# MIMXRT1042 register map
Vendor: nxp.com; File version: 1.0
CPU: CM7 r0p1, little endian, MPU, FPU, VTOR, 4 interrupt priority bits
Registers are 32-bit, read-write, reset 0x0 unless marked. A register's access mark holds for its fields unless they carry their own. Offsets are from the block's base; [hi:lo] are bit positions; {n}, {i} and the like mark numbered series; 'fields as' and 'values as' point back to an identical list.

## CAN3 — CAN
Base 0x401D8000
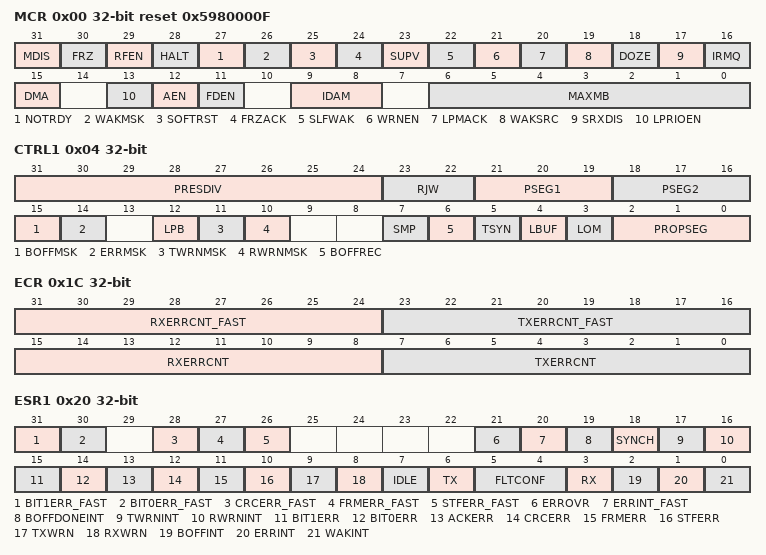
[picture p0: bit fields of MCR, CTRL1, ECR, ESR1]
0x00 MCR reset 0x5980000F — Module Configuration Register
  [31] MDIS — Module Disable
    0=flexcan_enabled (Enable the FlexCAN module.); 1=flexcan_disabled (Disable the FlexCAN module.)
  [30] FRZ — Freeze Enable
    0=freeze_mode_disabled (Not enabled to enter Freeze mode.); 1=freeze_mode_enabled (Enabled to enter Freeze mode.)
  [29] RFEN — Rx FIFO Enable
    0=id2 (Rx FIFO not enabled.); 1=id4 (Rx FIFO enabled.)
  [28] HALT — Halt FlexCAN
    0=HALT_disable (No Freeze mode request.); 1=HALT_enable (Enters Freeze mode if the FRZ bit is asserted.)
  [27] NOTRDY ro — FlexCAN Not Ready
    0=id1 (FlexCAN module is either in Normal mode, Listen-Only mode, or Loop-Back mode.); 1=id2 (FlexCAN module is either in Disable mode, Doze mode, Stop mode, or Freeze mode.)
  [26] WAKMSK — Wake Up Interrupt Mask
    0=wakeup_interrupt_disabled (Wake Up interrupt is disabled.); 1=wakeup_interrupt_enabled (Wake Up interrupt is enabled.)
  [25] SOFTRST — Soft Reset
    0=SOFTRST_no_reset_request (No reset request.); 1=SOFTRST_reset_registers (Resets the registers affected by soft reset.)
  [24] FRZACK ro — Freeze Mode Acknowledge
    0=freeze_mode_no (FlexCAN not in Freeze mode, prescaler running.); 1=freeze_mode_yes (FlexCAN in Freeze mode, prescaler stopped.)
  [23] SUPV — Supervisor Mode
    0=id2 (FlexCAN is in User mode. Affected registers allow both Supervisor and Unrestricted accesses.); 1=id4 (FlexCAN is in Supervisor mode. Affected registers allow only Supervisor access. Unrestricted access behaves as though the access was done to an unimplemented register location.)
  [22] SLFWAK — Self Wake Up
    0=self_wakeup_disabled (FlexCAN Self Wake Up feature is disabled.); 1=self_wakeup_enabled (FlexCAN Self Wake Up feature is enabled.)
  [21] WRNEN — Warning Interrupt Enable
    0=TWRNINT_RWRNINT_inactive (TWRNINT and RWRNINT bits are zero, independent of the values in the error counters.); 1=TWRNINT_RWRNINT_active (TWRNINT and RWRNINT bits are set when the respective error counter transitions from less than 96 to greater than or equal to 96.)
  [20] LPMACK ro — Low-Power Mode Acknowledge
    0=low_power_no (FlexCAN is not in a low-power mode.); 1=low_power_yes (FlexCAN is in a low-power mode.)
  [19] WAKSRC — Wake Up Source
    0=unfiltered_rx_input (FlexCAN uses the unfiltered Rx input to detect recessive to dominant edges on the CAN bus.); 1=filtered_rx_input (FlexCAN uses the filtered Rx input to detect recessive to dominant edges on the CAN bus.)
  [18] DOZE — Doze Mode Enable
    0=low_power_doze_disabled (FlexCAN is not enabled to enter low-power mode when Doze mode is requested.); 1=low_power_doze_enabled (FlexCAN is enabled to enter low-power mode when Doze mode is requested.)
  [17] SRXDIS — Self Reception Disable
    0=self_reception_enabled; 1=self_reception_disabled
  [16] IRMQ — Individual Rx Masking And Queue Enable
    0=individual_rx_masking_disabled (Individual Rx masking and queue feature are disabled. For backward compatibility with legacy applications, the reading of C/S word locks the MB even if it is EMPTY.); 1=individual_rx_masking_enabled (Individual Rx masking and queue feature are enabled.)
  [15] DMA — DMA Enable
    0=id2 (DMA feature for RX FIFO disabled.); 1=id4 (DMA feature for RX FIFO enabled.)
  [13] LPRIOEN — Local Priority Enable
    0=local_priority_disabled; 1=local_priority_enabled
  [12] AEN — Abort Enable
    0=abort_disabled; 1=abort_enabled
  [11] FDEN — CAN FD operation enable
    0=CAN_FD_disabled (CAN FD is disabled. FlexCAN is able to receive and transmit messages in CAN 2.0 format.); 1=CAN_FD_enabled (CAN FD is enabled. FlexCAN is able to receive and transmit messages in both CAN FD and CAN 2.0 formats.)
  [9:8] IDAM — ID Acceptance Mode
    0=one_full_ID (Format A: One full ID (standard and extended) per ID filter table element.); 1=two_full_ID (Format B: Two full standard IDs or two partial 14-bit (standard and extended) IDs per ID filter table element.); 2=four_partial_ID (Format C: Four partial 8-bit standard IDs per ID filter table element.); 3=all_frames_rejected (Format D: All frames rejected.)
  [6:0] MAXMB — Number Of The Last Message Buffer
0x04 CTRL1 — Control 1 Register
  [31:24] PRESDIV — Prescaler Division Factor
  [23:22] RJW — Resync Jump Width
  [21:19] PSEG1 — Phase Segment 1
  [18:16] PSEG2 — Phase Segment 2
  [15] BOFFMSK — Bus Off Interrupt Mask
    0=bus_off_int_disabled (Bus Off interrupt disabled.); 1=bus_off_int_enabled (Bus Off interrupt enabled.)
  [14] ERRMSK — Error Interrupt Mask
    0=error_int_disabled (Error interrupt disabled.); 1=error_int_enabled (Error interrupt enabled.)
  [12] LPB — Loop Back Mode
    0=loopback_disabled; 1=loopback_enabled
  [11] TWRNMSK — Tx Warning Interrupt Mask
    0=tx_warning_int_disabled (Tx Warning interrupt disabled.); 1=tx_warning_int_enabled (Tx Warning interrupt enabled.)
  [10] RWRNMSK — Rx Warning Interrupt Mask
    0=rx_warning_int_disabled (Rx Warning interrupt disabled.); 1=rx_warning_int_enabled (Rx Warning interrupt enabled.)
  [7] SMP — CAN Bit Sampling
    0=one_sample (Just one sample is used to determine the bit value.); 1=Three samples are used to determine the value of the received bit: the regular one (sample point) and two preceding samples; a majority rule is used
  [6] BOFFREC — Bus Off Recovery
    0=auto_recover_enabled (Automatic recovering from Bus Off state enabled.); 1=auto_recover_disabled (Automatic recovering from Bus Off state disabled.)
  [5] TSYN — Timer Sync
    0=timer_sync_disabled (Timer sync feature disabled); 1=timer_sync_enabled (Timer sync feature enabled)
  [4] LBUF — Lowest Buffer Transmitted First
    0=highest_buffer_first (Buffer with highest priority is transmitted first.); 1=lowest_buffer_first (Lowest number buffer is transmitted first.)
  [3] LOM — Listen-Only Mode
    0=listen_only_mode_disabled (Listen-Only mode is deactivated.); 1=listen_only_mode_enabled (FlexCAN module operates in Listen-Only mode.)
  [2:0] PROPSEG — Propagation Segment
0x08 TIMER — Free Running Timer
  [15:0] TIMER — Timer Value
0x10 RXMGMASK reset not defined — Rx Mailboxes Global Mask Register
  [31:0] MG — Rx Mailboxes Global Mask Bits
0x14 RX14MASK reset not defined
  [31:0] RX14M — Rx Buffer 14 Mask Bits
0x18 RX15MASK reset not defined
  [31:0] RX15M — Rx Buffer 15 Mask Bits
0x1C ECR — Error Counter
  [31:24] RXERRCNT_FAST — Receive Error Counter for fast bits
  [23:16] TXERRCNT_FAST — Transmit Error Counter for fast bits
  [15:8] RXERRCNT — Receive Error Counter
  [7:0] TXERRCNT — Transmit Error Counter
0x20 ESR1 — Error and Status 1 Register
  [31] BIT1ERR_FAST ro — Bit1 Error in the Data Phase of CAN FD frames with the BRS bit set
    0=bit1_error_no (No such occurrence.); 1=bit1_error_yes (At least one bit sent as recessive is received as dominant.)
  [30] BIT0ERR_FAST ro — Bit0 Error in the Data Phase of CAN FD frames with the BRS bit set
    0=bit0_error_no (No such occurrence.); 1=bit0_error_yes (At least one bit sent as dominant is received as recessive.)
  [28] CRCERR_FAST ro — Cyclic Redundancy Check Error in the CRC field of CAN FD frames with the BRS bit set
    0=CRC_error_no (No such occurrence.); 1=CRC_error_yes (A CRC error occurred since last read of this register.)
  [27] FRMERR_FAST ro — Form Error in the Data Phase of CAN FD frames with the BRS bit set
    0=form_error_no (No such occurrence.); 1=form_error_yes (A form error occurred since last read of this register.)
  [26] STFERR_FAST ro — Stuffing Error in the Data Phase of CAN FD frames with the BRS bit set
    0=stuffing_error_no (No such occurrence.); 1=stuffing_error_yes (A stuffing error occurred since last read of this register.)
  [21] ERROVR write-1-clears — Error Overrun
    0=overrun_not_occurred (Overrun has not occurred.); 1=overrun_occurred (Overrun has occurred.)
  [20] ERRINT_FAST write-1-clears — Error interrupt for errors detected in Data Phase of CAN FD frames with BRS bit set
    0=errors_data_phase_no (No such occurrence.); 1=errors_data_phase_yes (Indicates setting of any error bit detected in the data phase of CAN FD frames with the BRS bit set.)
  [19] BOFFDONEINT write-1-clears — Bus Off Done Interrupt
    0=bus_off_not_done (No such occurrence.); 1=bus_off_done (FlexCAN module has completed Bus Off process.)
  [18] SYNCH ro — CAN Synchronization Status
    0=CAN_bus_sync_no (FlexCAN is not synchronized to the CAN bus.); 1=CAN_bus_sync_yes (FlexCAN is synchronized to the CAN bus.)
  [17] TWRNINT write-1-clears — Tx Warning Interrupt Flag
    0=Tx_warning_int_no (No such occurrence.); 1=Tx_warning_int_yes (The Tx error counter transitioned from less than 96 to greater than or equal to 96.)
  [16] RWRNINT write-1-clears — Rx Warning Interrupt Flag
    0=Rx_warning_int_no (No such occurrence.); 1=Rx_warning_int_yes (The Rx error counter transitioned from less than 96 to greater than or equal to 96.)
  [15] BIT1ERR ro — Bit1 Error
    values as BIT1ERR_FAST
  [14] BIT0ERR ro — Bit0 Error
    values as BIT0ERR_FAST
  [13] ACKERR ro — Acknowledge Error
    0=ACK_error_no (No such occurrence.); 1=ACK_error_yes (An ACK error occurred since last read of this register.)
  [12] CRCERR ro — Cyclic Redundancy Check Error
    values as CRCERR_FAST
  [11] FRMERR ro — Form Error
    0=form_error_no (No such occurrence.); 1=form_error_yes (A Form Error occurred since last read of this register.)
  [10] STFERR ro — Stuffing Error
    values as STFERR_FAST
  [9] TXWRN ro — TX Error Warning
    0=TXERRCNT_LT_96 (No such occurrence.); 1=TXERRCNT_GTE_96 (TXERRCNT is greater than or equal to 96.)
  [8] RXWRN ro — Rx Error Warning
    0=RXERRCNT_LT_96 (No such occurrence.); 1=RXERRCNT_GTE_96 (RXERRCNT is greater than or equal to 96.)
  [7] IDLE ro
    0=can_bus_not_idle (No such occurrence.); 1=can_bus_idle (CAN bus is now IDLE.)
  [6] TX ro — FlexCAN In Transmission
    0=transmit_message_no (FlexCAN is not transmitting a message.); 1=transmit_message_yes (FlexCAN is transmitting a message.)
  [5:4] FLTCONF ro — Fault Confinement State
    0=error_active; 1=error_passive; 0b1x=bus_off
  [3] RX ro — FlexCAN In Reception
    0=DISABLE (FlexCAN is not receiving a message.); 1=ENABLE (FlexCAN is receiving a message.)
  [2] BOFFINT write-1-clears — Bus Off Interrupt
    0=DISABLE (No such occurrence.); 1=ENABLE (FlexCAN module entered Bus Off state.)
  [1] ERRINT write-1-clears — Error Interrupt
    0=DISABLE (No such occurrence.); 1=ENABLE (Indicates setting of any error bit in the Error and Status register.)
  [0] WAKINT write-1-clears — Wake-Up Interrupt
    0=DISABLE (No such occurrence.); 1=ENABLE (Indicates a recessive to dominant transition was received on the CAN bus.)
0x24 IMASK2 — Interrupt Masks 2 Register
  [31:0] BUF63TO32M — Buffer MBi Mask
0x28 IMASK1 — Interrupt Masks 1 Register
  [31:0] BUF31TO0M — Buffer MBi Mask
0x2C IFLAG2 write-1-clears — Interrupt Flags 2 Register
  [31:0] BUF63TO32I write-1-clears — Buffer MBi Interrupt
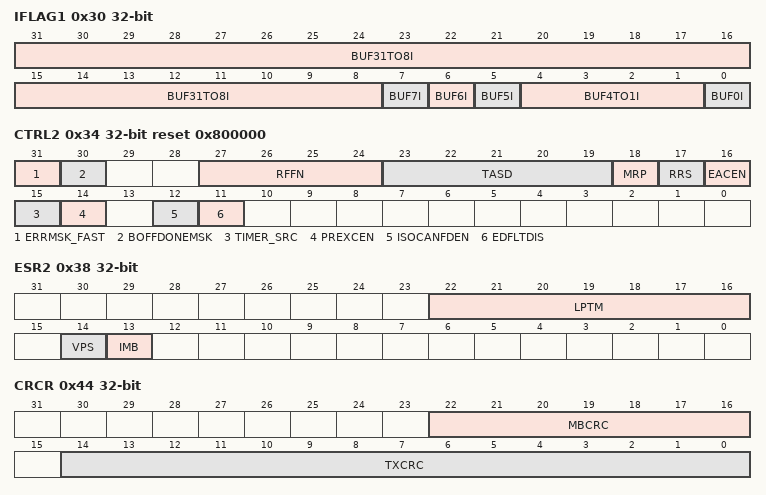
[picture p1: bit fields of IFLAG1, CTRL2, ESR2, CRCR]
0x30 IFLAG1 write-1-clears — Interrupt Flags 1 Register
  [31:8] BUF31TO8I write-1-clears — Buffer MBi Interrupt
  [7] BUF7I write-1-clears — Buffer MB7 Interrupt Or Rx FIFO Overflow
    0=id2 (No occurrence of MB7 completing transmission/reception when MCR[RFEN]=0, or of Rx FIFO overflow when MCR[RFEN]=1); 1=id4 (MB7 completed transmission/reception when MCR[RFEN]=0, or Rx FIFO overflow when MCR[RFEN]=1)
  [6] BUF6I write-1-clears — Buffer MB6 Interrupt Or Rx FIFO Warning
    0=id2 (No occurrence of MB6 completing transmission/reception when MCR[RFEN]=0, or of Rx FIFO almost full when MCR[RFEN]=1); 1=id4 (MB6 completed transmission/reception when MCR[RFEN]=0, or Rx FIFO almost full when MCR[RFEN]=1)
  [5] BUF5I write-1-clears — Buffer MB5 Interrupt Or Frames available in Rx FIFO
    0=id2 (No occurrence of MB5 completing transmission/reception when MCR[RFEN]=0, or of frame(s) available in the FIFO, when MCR[RFEN]=1); 1=id4 (MB5 completed transmission/reception when MCR[RFEN]=0, or frame(s) available in the Rx FIFO when MCR[RFEN]=1. It generates a DMA request in case of MCR[RFEN] and MCR[DMA] are enabled.)
  [4:1] BUF4TO1I write-1-clears — Buffer MBi Interrupt Or Reserved
  [0] BUF0I write-1-clears — Buffer MB0 Interrupt Or Clear FIFO bit
    0=buffer_Tx_Rx_not_complete (The corresponding buffer has no occurrence of successfully completed transmission or reception when MCR[RFEN]=0.); 1=buffer_Tx_Rx_complete (The corresponding buffer has successfully completed transmission or reception when MCR[RFEN]=0.)
0x34 CTRL2 reset 0x800000 — Control 2 Register
  [31] ERRMSK_FAST — Error Interrupt Mask for errors detected in the data phase of fast CAN FD frames
    0=DISABLE (ERRINT_FAST error interrupt disabled.); 1=ENABLE (ERRINT_FAST error interrupt enabled.)
  [30] BOFFDONEMSK — Bus Off Done Interrupt Mask
    0=DISABLE (Bus off done interrupt disabled.); 1=ENABLE (Bus off done interrupt enabled.)
  [27:24] RFFN — Number Of Rx FIFO Filters
  [23:19] TASD — Tx Arbitration Start Delay
  [18] MRP — Mailboxes Reception Priority
    0=id2 (Matching starts from Rx FIFO and continues on mailboxes.); 1=id4 (Matching starts from mailboxes and continues on Rx FIFO.)
  [17] RRS — Remote Request Storing
    0=remote_response_frame_not_generated (Remote response frame is generated.); 1=remote_response_frame_generated (Remote request frame is stored.)
  [16] EACEN — Entire Frame Arbitration Field Comparison Enable For Rx Mailboxes
    0=RTR_compare_no (Rx mailbox filter's IDE bit is always compared and RTR is never compared despite mask bits.); 1=RTR_compare_yes (Enables the comparison of both Rx mailbox filter's IDE and RTR bit with their corresponding bits within the incoming frame. Mask bits do apply.)
  [15] TIMER_SRC — Timer Source
    0=CAN_bit_clock (The free running timer is clocked by the CAN bit clock, which defines the baud rate on the CAN bus.); 1=external_clock (The free running timer is clocked by an external time tick. The period can be either adjusted to be equal to the baud rate on the CAN bus, or a different value as required. See the device-specific section for details about the external time tick.)
  [14] PREXCEN — Protocol Exception Enable
    0=DISABLE (Protocol exception is disabled.); 1=ENABLE (Protocol exception is enabled.)
  [12] ISOCANFDEN — ISO CAN FD Enable
    0=non_ISO (FlexCAN operates using the non-ISO CAN FD protocol.); 1=ISO (FlexCAN operates using the ISO CAN FD protocol (ISO 11898-1).)
  [11] EDFLTDIS — Edge Filter Disable
    0=ENABLE (Edge filter is enabled); 1=DISABLE (Edge filter is disabled)
0x38 ESR2 ro — Error and Status 2 Register
  [22:16] LPTM — Lowest Priority Tx Mailbox
  [14] VPS — Valid Priority Status
    0=invalid (Contents of IMB and LPTM are invalid.); 1=valid (Contents of IMB and LPTM are valid.)
  [13] IMB — Inactive Mailbox
    0=inactive_mailbox_no (If ESR2[VPS] is asserted, the ESR2[LPTM] is not an inactive mailbox.); 1=inactive_mailbox_yes (If ESR2[VPS] is asserted, there is at least one inactive mailbox. LPTM content is the number of the first one.)
0x44 CRCR ro — CRC Register
  [22:16] MBCRC — CRC Mailbox
  [14:0] TXCRC — Transmitted CRC value
0x48 RXFGMASK reset not defined — Rx FIFO Global Mask Register
  [31:0] FGM — Rx FIFO Global Mask Bits
0x4C RXFIR ro reset not defined — Rx FIFO Information Register
  [8:0] IDHIT — Identifier Acceptance Filter Hit Indicator
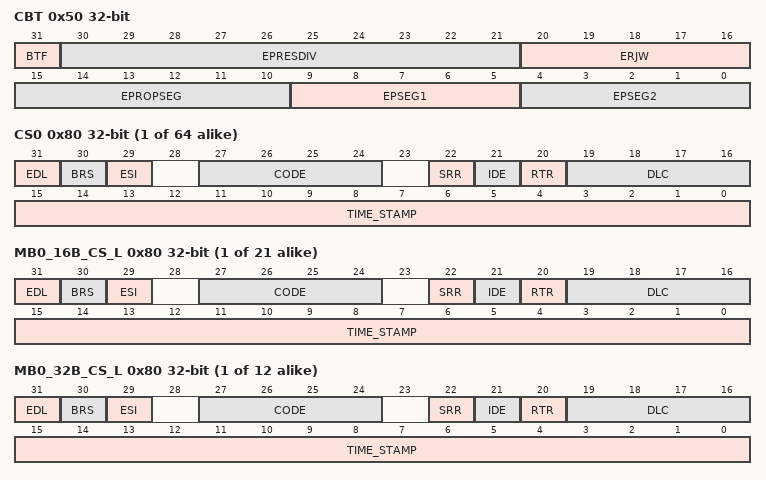
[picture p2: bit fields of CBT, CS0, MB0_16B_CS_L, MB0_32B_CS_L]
0x50 CBT — CAN Bit Timing Register
  [31] BTF — Bit Timing Format Enable
    0=DISABLE (Extended bit time definitions disabled.); 1=ENABLE (Extended bit time definitions enabled.)
  [30:21] EPRESDIV — Extended Prescaler Division Factor
  [20:16] ERJW — Extended Resync Jump Width
  [15:10] EPROPSEG — Extended Propagation Segment
  [9:5] EPSEG1 — Extended Phase Segment 1
  [4:0] EPSEG2 — Extended Phase Segment 2
{0x80+0x10*i} CS{i} (MB_SIZE view) (i=0..63) — Message Buffer {i} CS Register
  [31] EDL — Extended Data Length. This bit distinguishes between CAN format and CAN FD format frames. The EDL bit must not be set for Message Buffers configured to RANSWER with code field 0b1010.
  [30] BRS — Bit Rate Switch. This bit defines whether the bit rate is switched inside a CAN FD format frame.
  [29] ESI — Error State Indicator. This bit indicates if the transmitting node is error active or error passive.
  [27:24] CODE — Message Buffer Code. This 4-bit field can be accessed (read or write) by the CPU and by the FlexCAN module itself, as part of the message buffer matching and arbitration process.
  [22] SRR — Substitute Remote Request. Contains a fixed recessive bit.
  [21] IDE — ID Extended. One/zero for extended/standard format frame.
  [20] RTR — Remote Transmission Request. One/zero for remote/data frame.
  [19:16] DLC — Length of the data to be stored/transmitted.
  [15:0] TIME_STAMP — Free-Running Counter Time stamp. This 16-bit field is a copy of the Free-Running Timer, captured for Tx and Rx frames at the time when the beginning of the Identifier field appears on the CAN bus.
{0x80+0x18*i} MB{i}_16B_CS_L (MB_SIZE view) (i=0..20) — Message Buffer {i} CS Register
  fields as CS0
{0x80+0x28*i} MB{i}_32B_CS_L (MB_SIZE view) (i=0..11) — Message Buffer {i} CS Register
  fields as CS0
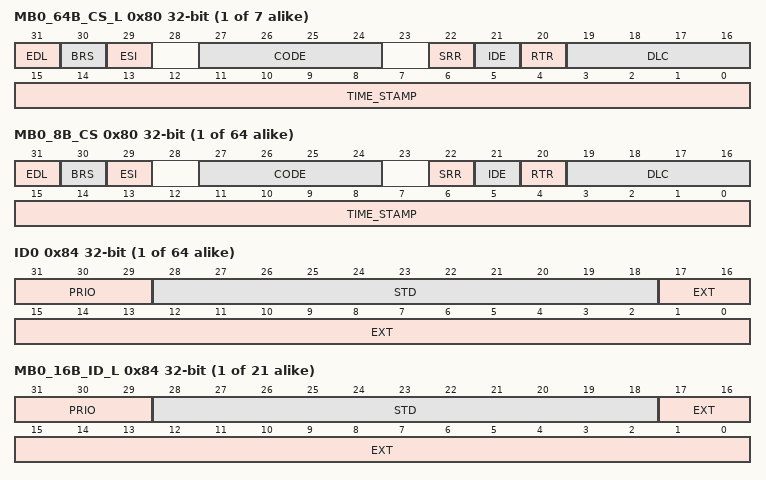
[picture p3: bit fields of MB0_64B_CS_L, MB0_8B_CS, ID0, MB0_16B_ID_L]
{0x80+0x48*i} MB{i}_64B_CS_L (MB_SIZE view) (i=0..6) — Message Buffer {i} CS Register
  fields as CS0
{0x80+0x10*i} MB{i}_8B_CS (MB_SIZE view) (i=0..63) — Message Buffer {i} CS Register
  fields as CS0
{0x84+0x10*i} ID{i} (MB_SIZE view) (i=0..63) — Message Buffer {i} ID Register
  [31:29] PRIO — Local priority. This 3-bit fieldis only used when LPRIO_EN bit is set in MCR and it only makes sense for Tx buffers. These bits are not transmitted. They are appended to the regular ID to define the transmission priority.
  [28:18] STD — Contains standard/extended (HIGH word) identifier of message buffer.
  [17:0] EXT — Contains extended (LOW word) identifier of message buffer.
{0x84+0x18*i} MB{i}_16B_ID_L (MB_SIZE view) (i=0..20) — Message Buffer {i} ID Register
  fields as ID0
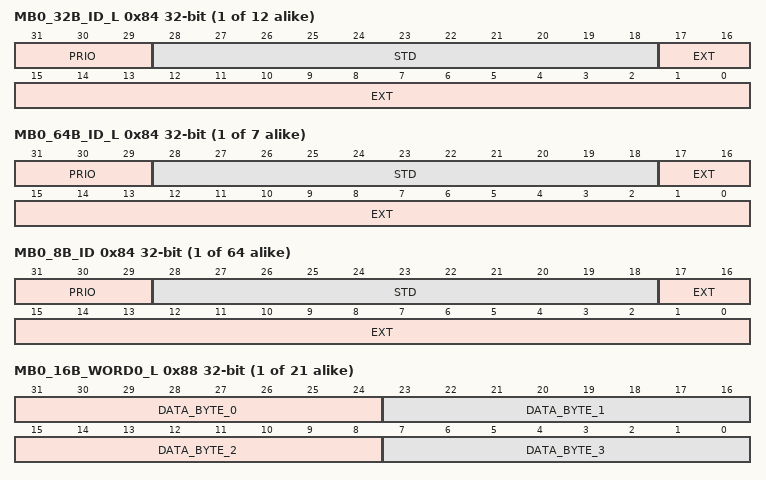
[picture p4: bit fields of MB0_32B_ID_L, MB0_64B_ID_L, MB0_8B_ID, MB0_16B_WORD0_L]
{0x84+0x28*i} MB{i}_32B_ID_L (MB_SIZE view) (i=0..11) — Message Buffer {i} ID Register
  fields as ID0
{0x84+0x48*i} MB{i}_64B_ID_L (MB_SIZE view) (i=0..6) — Message Buffer {i} ID Register
  fields as ID0
{0x84+0x10*i} MB{i}_8B_ID (MB_SIZE view) (i=0..63) — Message Buffer {i} ID Register
  fields as ID0
{0x88+0x18*i} MB{i}_16B_WORD0_L (MB_SIZE view) (i=0..20) — Message Buffer {i} WORD_16B Register
  [31:24] DATA_BYTE_0 — Data byte 3 of Rx/Tx frame.
  [23:16] DATA_BYTE_1 — Data byte 2 of Rx/Tx frame.
  [15:8] DATA_BYTE_2 — Data byte 1 of Rx/Tx frame.
  [7:0] DATA_BYTE_3 — Data byte 0 of Rx/Tx frame.
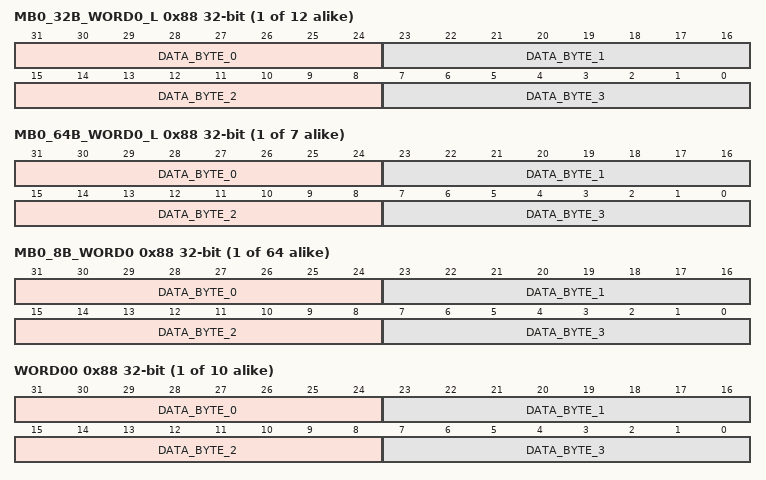
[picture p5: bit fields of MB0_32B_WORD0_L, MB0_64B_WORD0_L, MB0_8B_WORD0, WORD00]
{0x88+0x28*i} MB{i}_32B_WORD0_L (MB_SIZE view) (i=0..11) — Message Buffer {i} WORD_32B Register
  fields as MB0_16B_WORD0_L
{0x88+0x48*i} MB{i}_64B_WORD0_L (MB_SIZE view) (i=0..6) — Message Buffer {i} WORD_64B Register
  fields as MB0_16B_WORD0_L
{0x88+0x10*i} MB{i}_8B_WORD0 (MB_SIZE view) (i=0..63) — Message Buffer {i} WORD_8B Register
  fields as MB0_16B_WORD0_L
{0x88+0x10*i} WORD{i:02} (MB_SIZE view) (i=0..9) — Message Buffer {i} WORD0 Register
  fields as MB0_16B_WORD0_L
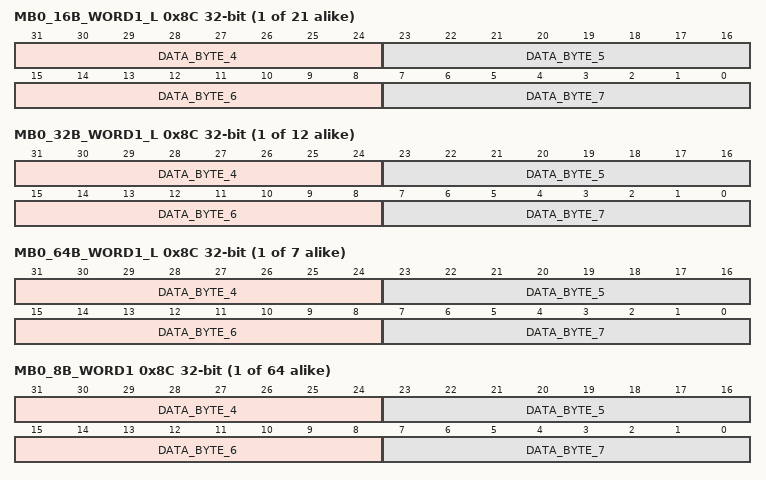
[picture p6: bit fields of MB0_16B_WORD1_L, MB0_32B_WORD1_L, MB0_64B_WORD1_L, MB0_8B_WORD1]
{0x8C+0x18*i} MB{i}_16B_WORD1_L (MB_SIZE view) (i=0..20) — Message Buffer {i} WORD_16B Register
  [31:24] DATA_BYTE_4 — Data byte 3 of Rx/Tx frame.
  [23:16] DATA_BYTE_5 — Data byte 2 of Rx/Tx frame.
  [15:8] DATA_BYTE_6 — Data byte 1 of Rx/Tx frame.
  [7:0] DATA_BYTE_7 — Data byte 0 of Rx/Tx frame.
{0x8C+0x28*i} MB{i}_32B_WORD1_L (MB_SIZE view) (i=0..11) — Message Buffer {i} WORD_32B Register
  fields as MB0_16B_WORD1_L
{0x8C+0x48*i} MB{i}_64B_WORD1_L (MB_SIZE view) (i=0..6) — Message Buffer {i} WORD_64B Register
  fields as MB0_16B_WORD1_L
{0x8C+0x10*i} MB{i}_8B_WORD1 (MB_SIZE view) (i=0..63) — Message Buffer {i} WORD_8B Register
  fields as MB0_16B_WORD1_L
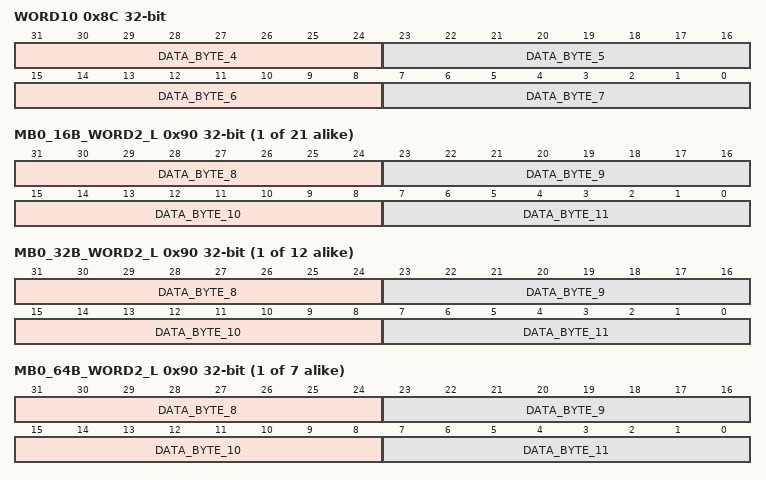
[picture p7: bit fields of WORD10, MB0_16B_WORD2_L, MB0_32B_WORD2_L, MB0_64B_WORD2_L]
0x8C WORD10 (MB_SIZE view) — Message Buffer 0 WORD1 Register
  fields as MB0_16B_WORD1_L
{0x90+0x18*i} MB{i}_16B_WORD2_L (MB_SIZE view) (i=0..20) — Message Buffer {i} WORD_16B Register
  [31:24] DATA_BYTE_8 — Data byte 3 of Rx/Tx frame.
  [23:16] DATA_BYTE_9 — Data byte 2 of Rx/Tx frame.
  [15:8] DATA_BYTE_10 — Data byte 1 of Rx/Tx frame.
  [7:0] DATA_BYTE_11 — Data byte 0 of Rx/Tx frame.
{0x90+0x28*i} MB{i}_32B_WORD2_L (MB_SIZE view) (i=0..11) — Message Buffer {i} WORD_32B Register
  fields as MB0_16B_WORD2_L
{0x90+0x48*i} MB{i}_64B_WORD2_L (MB_SIZE view) (i=0..6) — Message Buffer {i} WORD_64B Register
  fields as MB0_16B_WORD2_L
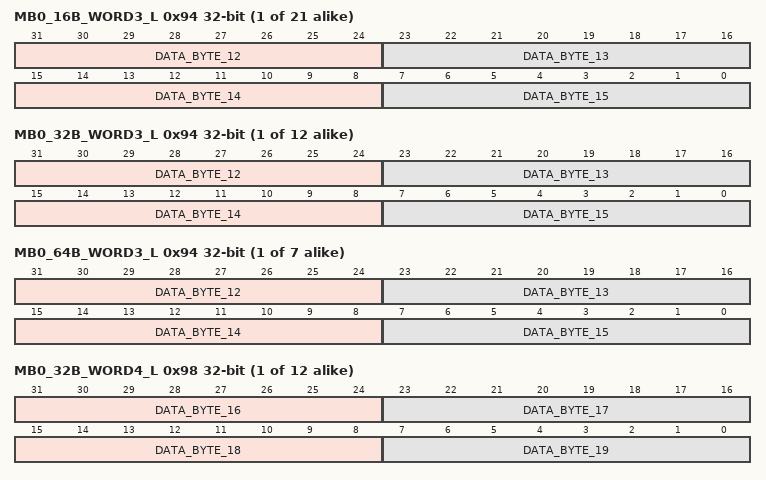
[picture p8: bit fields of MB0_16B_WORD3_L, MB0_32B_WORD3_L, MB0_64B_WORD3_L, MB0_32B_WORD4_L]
{0x94+0x18*i} MB{i}_16B_WORD3_L (MB_SIZE view) (i=0..20) — Message Buffer {i} WORD_16B Register
  [31:24] DATA_BYTE_12 — Data byte 3 of Rx/Tx frame.
  [23:16] DATA_BYTE_13 — Data byte 2 of Rx/Tx frame.
  [15:8] DATA_BYTE_14 — Data byte 1 of Rx/Tx frame.
  [7:0] DATA_BYTE_15 — Data byte 0 of Rx/Tx frame.
{0x94+0x28*i} MB{i}_32B_WORD3_L (MB_SIZE view) (i=0..11) — Message Buffer {i} WORD_32B Register
  fields as MB0_16B_WORD3_L
{0x94+0x48*i} MB{i}_64B_WORD3_L (MB_SIZE view) (i=0..6) — Message Buffer {i} WORD_64B Register
  fields as MB0_16B_WORD3_L
{0x98+0x28*i} MB{i}_32B_WORD4_L (MB_SIZE view) (i=0..11) — Message Buffer {i} WORD_32B Register
  [31:24] DATA_BYTE_16 — Data byte 3 of Rx/Tx frame.
  [23:16] DATA_BYTE_17 — Data byte 2 of Rx/Tx frame.
  [15:8] DATA_BYTE_18 — Data byte 1 of Rx/Tx frame.
  [7:0] DATA_BYTE_19 — Data byte 0 of Rx/Tx frame.
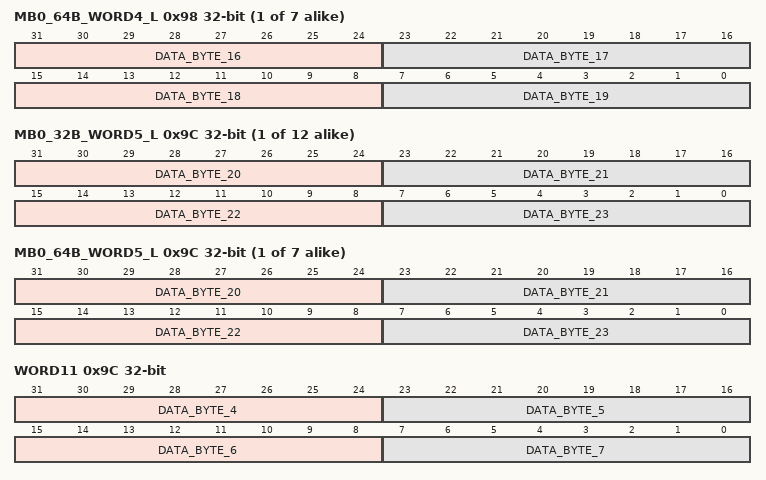
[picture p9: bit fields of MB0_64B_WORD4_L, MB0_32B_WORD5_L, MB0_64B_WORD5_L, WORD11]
{0x98+0x48*i} MB{i}_64B_WORD4_L (MB_SIZE view) (i=0..6) — Message Buffer {i} WORD_64B Register
  fields as MB0_32B_WORD4_L
{0x9C+0x28*i} MB{i}_32B_WORD5_L (MB_SIZE view) (i=0..11) — Message Buffer {i} WORD_32B Register
  [31:24] DATA_BYTE_20 — Data byte 3 of Rx/Tx frame.
  [23:16] DATA_BYTE_21 — Data byte 2 of Rx/Tx frame.
  [15:8] DATA_BYTE_22 — Data byte 1 of Rx/Tx frame.
  [7:0] DATA_BYTE_23 — Data byte 0 of Rx/Tx frame.
{0x9C+0x48*i} MB{i}_64B_WORD5_L (MB_SIZE view) (i=0..6) — Message Buffer {i} WORD_64B Register
  fields as MB0_32B_WORD5_L
0x9C WORD11 (MB_SIZE view) — Message Buffer 1 WORD1 Register
  fields as MB0_16B_WORD1_L
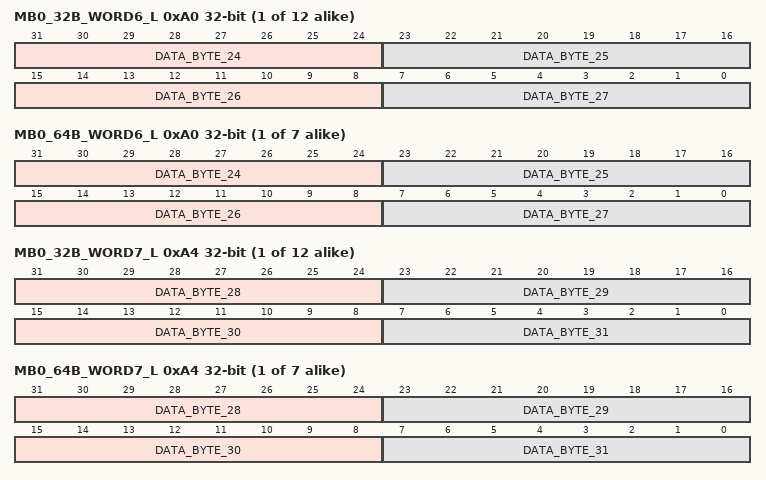
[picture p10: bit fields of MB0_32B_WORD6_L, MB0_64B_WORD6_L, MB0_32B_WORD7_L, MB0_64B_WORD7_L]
{0xA0+0x28*i} MB{i}_32B_WORD6_L (MB_SIZE view) (i=0..11) — Message Buffer {i} WORD_32B Register
  [31:24] DATA_BYTE_24 — Data byte 3 of Rx/Tx frame.
  [23:16] DATA_BYTE_25 — Data byte 2 of Rx/Tx frame.
  [15:8] DATA_BYTE_26 — Data byte 1 of Rx/Tx frame.
  [7:0] DATA_BYTE_27 — Data byte 0 of Rx/Tx frame.
{0xA0+0x48*i} MB{i}_64B_WORD6_L (MB_SIZE view) (i=0..6) — Message Buffer {i} WORD_64B Register
  fields as MB0_32B_WORD6_L
{0xA4+0x28*i} MB{i}_32B_WORD7_L (MB_SIZE view) (i=0..11) — Message Buffer {i} WORD_32B Register
  [31:24] DATA_BYTE_28 — Data byte 3 of Rx/Tx frame.
  [23:16] DATA_BYTE_29 — Data byte 2 of Rx/Tx frame.
  [15:8] DATA_BYTE_30 — Data byte 1 of Rx/Tx frame.
  [7:0] DATA_BYTE_31 — Data byte 0 of Rx/Tx frame.
{0xA4+0x48*i} MB{i}_64B_WORD7_L (MB_SIZE view) (i=0..6) — Message Buffer {i} WORD_64B Register
  fields as MB0_32B_WORD7_L
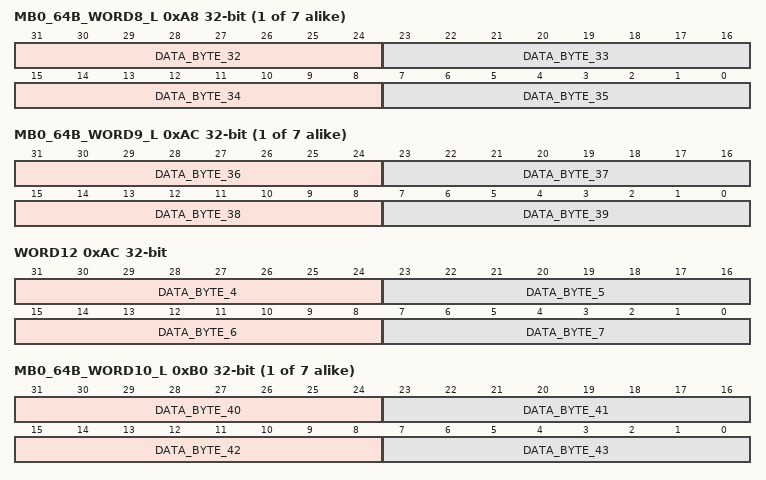
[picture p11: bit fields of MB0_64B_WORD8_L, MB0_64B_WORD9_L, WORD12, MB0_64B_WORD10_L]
{0xA8+0x48*i} MB{i}_64B_WORD8_L (MB_SIZE view) (i=0..6) — Message Buffer {i} WORD_64B Register
  [31:24] DATA_BYTE_32 — Data byte 3 of Rx/Tx frame.
  [23:16] DATA_BYTE_33 — Data byte 2 of Rx/Tx frame.
  [15:8] DATA_BYTE_34 — Data byte 1 of Rx/Tx frame.
  [7:0] DATA_BYTE_35 — Data byte 0 of Rx/Tx frame.
{0xAC+0x48*i} MB{i}_64B_WORD9_L (MB_SIZE view) (i=0..6) — Message Buffer {i} WORD_64B Register
  [31:24] DATA_BYTE_36 — Data byte 3 of Rx/Tx frame.
  [23:16] DATA_BYTE_37 — Data byte 2 of Rx/Tx frame.
  [15:8] DATA_BYTE_38 — Data byte 1 of Rx/Tx frame.
  [7:0] DATA_BYTE_39 — Data byte 0 of Rx/Tx frame.
0xAC WORD12 (MB_SIZE view) — Message Buffer 2 WORD1 Register
  fields as MB0_16B_WORD1_L
{0xB0+0x48*i} MB{i}_64B_WORD10_L (MB_SIZE view) (i=0..6) — Message Buffer {i} WORD_64B Register
  [31:24] DATA_BYTE_40 — Data byte 3 of Rx/Tx frame.
  [23:16] DATA_BYTE_41 — Data byte 2 of Rx/Tx frame.
  [15:8] DATA_BYTE_42 — Data byte 1 of Rx/Tx frame.
  [7:0] DATA_BYTE_43 — Data byte 0 of Rx/Tx frame.
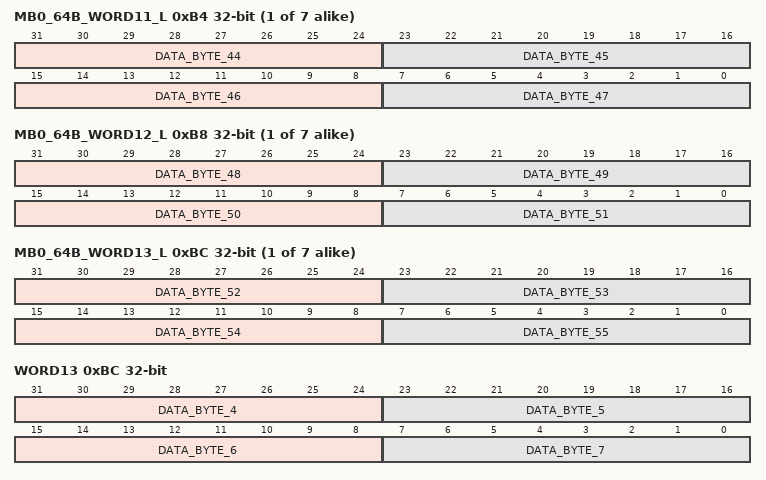
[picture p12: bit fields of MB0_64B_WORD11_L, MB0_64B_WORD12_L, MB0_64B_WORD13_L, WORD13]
{0xB4+0x48*i} MB{i}_64B_WORD11_L (MB_SIZE view) (i=0..6) — Message Buffer {i} WORD_64B Register
  [31:24] DATA_BYTE_44 — Data byte 3 of Rx/Tx frame.
  [23:16] DATA_BYTE_45 — Data byte 2 of Rx/Tx frame.
  [15:8] DATA_BYTE_46 — Data byte 1 of Rx/Tx frame.
  [7:0] DATA_BYTE_47 — Data byte 0 of Rx/Tx frame.
{0xB8+0x48*i} MB{i}_64B_WORD12_L (MB_SIZE view) (i=0..6) — Message Buffer {i} WORD_64B Register
  [31:24] DATA_BYTE_48 — Data byte 3 of Rx/Tx frame.
  [23:16] DATA_BYTE_49 — Data byte 2 of Rx/Tx frame.
  [15:8] DATA_BYTE_50 — Data byte 1 of Rx/Tx frame.
  [7:0] DATA_BYTE_51 — Data byte 0 of Rx/Tx frame.
{0xBC+0x48*i} MB{i}_64B_WORD13_L (MB_SIZE view) (i=0..6) — Message Buffer {i} WORD_64B Register
  [31:24] DATA_BYTE_52 — Data byte 3 of Rx/Tx frame.
  [23:16] DATA_BYTE_53 — Data byte 2 of Rx/Tx frame.
  [15:8] DATA_BYTE_54 — Data byte 1 of Rx/Tx frame.
  [7:0] DATA_BYTE_55 — Data byte 0 of Rx/Tx frame.
0xBC WORD13 (MB_SIZE view) — Message Buffer 3 WORD1 Register
  fields as MB0_16B_WORD1_L
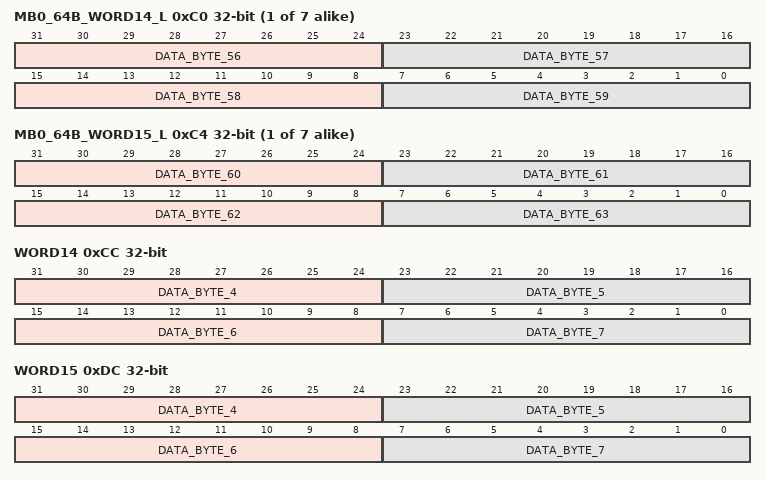
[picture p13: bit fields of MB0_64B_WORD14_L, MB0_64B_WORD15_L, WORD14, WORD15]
{0xC0+0x48*i} MB{i}_64B_WORD14_L (MB_SIZE view) (i=0..6) — Message Buffer {i} WORD_64B Register
  [31:24] DATA_BYTE_56 — Data byte 3 of Rx/Tx frame.
  [23:16] DATA_BYTE_57 — Data byte 2 of Rx/Tx frame.
  [15:8] DATA_BYTE_58 — Data byte 1 of Rx/Tx frame.
  [7:0] DATA_BYTE_59 — Data byte 0 of Rx/Tx frame.
{0xC4+0x48*i} MB{i}_64B_WORD15_L (MB_SIZE view) (i=0..6) — Message Buffer {i} WORD_64B Register
  [31:24] DATA_BYTE_60 — Data byte 3 of Rx/Tx frame.
  [23:16] DATA_BYTE_61 — Data byte 2 of Rx/Tx frame.
  [15:8] DATA_BYTE_62 — Data byte 1 of Rx/Tx frame.
  [7:0] DATA_BYTE_63 — Data byte 0 of Rx/Tx frame.
0xCC WORD14 (MB_SIZE view) — Message Buffer 4 WORD1 Register
  fields as MB0_16B_WORD1_L
0xDC WORD15 (MB_SIZE view) — Message Buffer 5 WORD1 Register
  fields as MB0_16B_WORD1_L
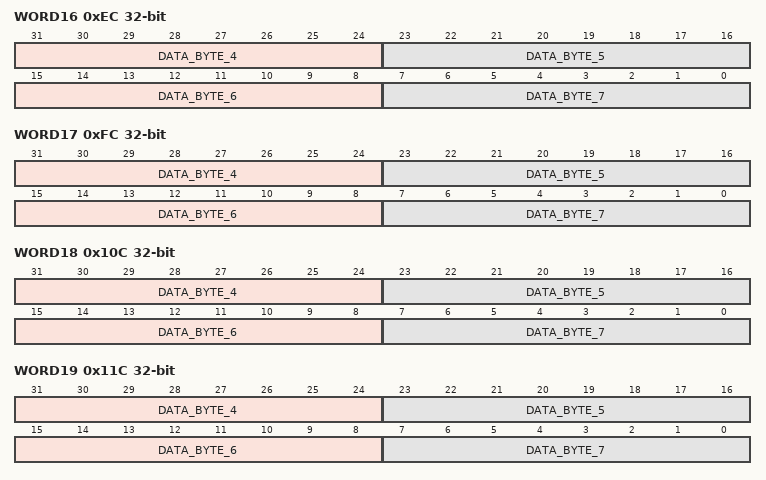
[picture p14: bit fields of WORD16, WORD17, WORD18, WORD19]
0xEC WORD16 (MB_SIZE view) — Message Buffer 6 WORD1 Register
  fields as MB0_16B_WORD1_L
0xFC WORD17 (MB_SIZE view) — Message Buffer 7 WORD1 Register
  fields as MB0_16B_WORD1_L
0x10C WORD18 (MB_SIZE view) — Message Buffer 8 WORD1 Register
  fields as MB0_16B_WORD1_L
0x11C WORD19 (MB_SIZE view) — Message Buffer 9 WORD1 Register
  fields as MB0_16B_WORD1_L
0x128 WORD010 (MB_SIZE view) — Message Buffer 10 WORD0 Register
  fields as MB0_16B_WORD0_L
0x12C WORD110 (MB_SIZE view) — Message Buffer 10 WORD1 Register
  fields as MB0_16B_WORD1_L
0x138 WORD011 (MB_SIZE view) — Message Buffer 11 WORD0 Register
  fields as MB0_16B_WORD0_L
0x13C WORD111 (MB_SIZE view) — Message Buffer 11 WORD1 Register
  fields as MB0_16B_WORD1_L
0x148 WORD012 (MB_SIZE view) — Message Buffer 12 WORD0 Register
  fields as MB0_16B_WORD0_L
0x14C WORD112 (MB_SIZE view) — Message Buffer 12 WORD1 Register
  fields as MB0_16B_WORD1_L
0x158 WORD013 (MB_SIZE view) — Message Buffer 13 WORD0 Register
  fields as MB0_16B_WORD0_L
0x15C WORD113 (MB_SIZE view) — Message Buffer 13 WORD1 Register
  fields as MB0_16B_WORD1_L
0x168 WORD014 (MB_SIZE view) — Message Buffer 14 WORD0 Register
  fields as MB0_16B_WORD0_L
0x16C WORD114 (MB_SIZE view) — Message Buffer 14 WORD1 Register
  fields as MB0_16B_WORD1_L
0x178 WORD015 (MB_SIZE view) — Message Buffer 15 WORD0 Register
  fields as MB0_16B_WORD0_L
0x17C WORD115 (MB_SIZE view) — Message Buffer 15 WORD1 Register
  fields as MB0_16B_WORD1_L
0x188 WORD016 (MB_SIZE view) — Message Buffer 16 WORD0 Register
  fields as MB0_16B_WORD0_L
0x18C WORD116 (MB_SIZE view) — Message Buffer 16 WORD1 Register
  fields as MB0_16B_WORD1_L
0x198 WORD017 (MB_SIZE view) — Message Buffer 17 WORD0 Register
  fields as MB0_16B_WORD0_L
0x19C WORD117 (MB_SIZE view) — Message Buffer 17 WORD1 Register
  fields as MB0_16B_WORD1_L
0x1A8 WORD018 (MB_SIZE view) — Message Buffer 18 WORD0 Register
  fields as MB0_16B_WORD0_L
0x1AC WORD118 (MB_SIZE view) — Message Buffer 18 WORD1 Register
  fields as MB0_16B_WORD1_L
{0x88+0x10*i} WORD{i:03} (MB_SIZE view) (i=19..63) — Message Buffer {i} WORD0 Register
  fields as MB0_16B_WORD0_L
0x1BC WORD119 (MB_SIZE view) — Message Buffer 19 WORD1 Register
  fields as MB0_16B_WORD1_L
0x1CC WORD120 (MB_SIZE view) — Message Buffer 20 WORD1 Register
  fields as MB0_16B_WORD1_L
0x1DC WORD121 (MB_SIZE view) — Message Buffer 21 WORD1 Register
  fields as MB0_16B_WORD1_L
0x1EC WORD122 (MB_SIZE view) — Message Buffer 22 WORD1 Register
  fields as MB0_16B_WORD1_L
0x1FC WORD123 (MB_SIZE view) — Message Buffer 23 WORD1 Register
  fields as MB0_16B_WORD1_L
0x20C WORD124 (MB_SIZE view) — Message Buffer 24 WORD1 Register
  fields as MB0_16B_WORD1_L
0x21C WORD125 (MB_SIZE view) — Message Buffer 25 WORD1 Register
  fields as MB0_16B_WORD1_L
0x22C WORD126 (MB_SIZE view) — Message Buffer 26 WORD1 Register
  fields as MB0_16B_WORD1_L
0x23C WORD127 (MB_SIZE view) — Message Buffer 27 WORD1 Register
  fields as MB0_16B_WORD1_L
0x24C WORD128 (MB_SIZE view) — Message Buffer 28 WORD1 Register
  fields as MB0_16B_WORD1_L
0x25C WORD129 (MB_SIZE view) — Message Buffer 29 WORD1 Register
  fields as MB0_16B_WORD1_L
0x26C WORD130 (MB_SIZE view) — Message Buffer 30 WORD1 Register
  fields as MB0_16B_WORD1_L
0x27C WORD131 (MB_SIZE view) — Message Buffer 31 WORD1 Register
  fields as MB0_16B_WORD1_L
{0x280+0x18*i} MB{i}_16B_CS_H (MB_SIZE view) (i=0..20) — Message Buffer {i} CS Register
  fields as CS0
{0x280+0x28*i} MB{i}_32B_CS_H (MB_SIZE view) (i=0..11) — Message Buffer {i} CS Register
  fields as CS0
{0x280+0x48*i} MB{i}_64B_CS_H (MB_SIZE view) (i=0..6) — Message Buffer {i} CS Register
  fields as CS0
{0x284+0x18*i} MB{i}_16B_ID_H (MB_SIZE view) (i=0..20) — Message Buffer {i} ID Register
  fields as ID0
{0x284+0x28*i} MB{i}_32B_ID_H (MB_SIZE view) (i=0..11) — Message Buffer {i} ID Register
  fields as ID0
{0x284+0x48*i} MB{i}_64B_ID_H (MB_SIZE view) (i=0..6) — Message Buffer {i} ID Register
  fields as ID0
{0x288+0x18*i} MB{i}_16B_WORD0_H (MB_SIZE view) (i=0..20) — Message Buffer {i} WORD_16B Register
  fields as MB0_16B_WORD0_L
{0x288+0x28*i} MB{i}_32B_WORD0_H (MB_SIZE view) (i=0..11) — Message Buffer {i} WORD_32B Register
  fields as MB0_16B_WORD0_L
{0x288+0x48*i} MB{i}_64B_WORD0_H (MB_SIZE view) (i=0..6) — Message Buffer {i} WORD_64B Register
  fields as MB0_16B_WORD0_L
{0x28C+0x18*i} MB{i}_16B_WORD1_H (MB_SIZE view) (i=0..20) — Message Buffer {i} WORD_16B Register
  fields as MB0_16B_WORD1_L
{0x28C+0x28*i} MB{i}_32B_WORD1_H (MB_SIZE view) (i=0..11) — Message Buffer {i} WORD_32B Register
  fields as MB0_16B_WORD1_L
{0x28C+0x48*i} MB{i}_64B_WORD1_H (MB_SIZE view) (i=0..6) — Message Buffer {i} WORD_64B Register
  fields as MB0_16B_WORD1_L
0x28C WORD132 (MB_SIZE view) — Message Buffer 32 WORD1 Register
  fields as MB0_16B_WORD1_L
{0x290+0x18*i} MB{i}_16B_WORD2_H (MB_SIZE view) (i=0..20) — Message Buffer {i} WORD_16B Register
  fields as MB0_16B_WORD2_L
{0x290+0x28*i} MB{i}_32B_WORD2_H (MB_SIZE view) (i=0..11) — Message Buffer {i} WORD_32B Register
  fields as MB0_16B_WORD2_L
{0x290+0x48*i} MB{i}_64B_WORD2_H (MB_SIZE view) (i=0..6) — Message Buffer {i} WORD_64B Register
  fields as MB0_16B_WORD2_L
{0x294+0x18*i} MB{i}_16B_WORD3_H (MB_SIZE view) (i=0..20) — Message Buffer {i} WORD_16B Register
  fields as MB0_16B_WORD3_L
{0x294+0x28*i} MB{i}_32B_WORD3_H (MB_SIZE view) (i=0..11) — Message Buffer {i} WORD_32B Register
  fields as MB0_16B_WORD3_L
{0x294+0x48*i} MB{i}_64B_WORD3_H (MB_SIZE view) (i=0..6) — Message Buffer {i} WORD_64B Register
  fields as MB0_16B_WORD3_L
{0x298+0x28*i} MB{i}_32B_WORD4_H (MB_SIZE view) (i=0..11) — Message Buffer {i} WORD_32B Register
  fields as MB0_32B_WORD4_L
{0x298+0x48*i} MB{i}_64B_WORD4_H (MB_SIZE view) (i=0..6) — Message Buffer {i} WORD_64B Register
  fields as MB0_32B_WORD4_L
{0x29C+0x28*i} MB{i}_32B_WORD5_H (MB_SIZE view) (i=0..11) — Message Buffer {i} WORD_32B Register
  fields as MB0_32B_WORD5_L
{0x29C+0x48*i} MB{i}_64B_WORD5_H (MB_SIZE view) (i=0..6) — Message Buffer {i} WORD_64B Register
  fields as MB0_32B_WORD5_L
0x29C WORD133 (MB_SIZE view) — Message Buffer 33 WORD1 Register
  fields as MB0_16B_WORD1_L
{0x2A0+0x28*i} MB{i}_32B_WORD6_H (MB_SIZE view) (i=0..11) — Message Buffer {i} WORD_32B Register
  fields as MB0_32B_WORD6_L
{0x2A0+0x48*i} MB{i}_64B_WORD6_H (MB_SIZE view) (i=0..6) — Message Buffer {i} WORD_64B Register
  fields as MB0_32B_WORD6_L
{0x2A4+0x28*i} MB{i}_32B_WORD7_H (MB_SIZE view) (i=0..11) — Message Buffer {i} WORD_32B Register
  fields as MB0_32B_WORD7_L
{0x2A4+0x48*i} MB{i}_64B_WORD7_H (MB_SIZE view) (i=0..6) — Message Buffer {i} WORD_64B Register
  fields as MB0_32B_WORD7_L
{0x2A8+0x48*i} MB{i}_64B_WORD8_H (MB_SIZE view) (i=0..6) — Message Buffer {i} WORD_64B Register
  fields as MB0_64B_WORD8_L
{0x2AC+0x48*i} MB{i}_64B_WORD9_H (MB_SIZE view) (i=0..6) — Message Buffer {i} WORD_64B Register
  fields as MB0_64B_WORD9_L
0x2AC WORD134 (MB_SIZE view) — Message Buffer 34 WORD1 Register
  fields as MB0_16B_WORD1_L
{0x2B0+0x48*i} MB{i}_64B_WORD10_H (MB_SIZE view) (i=0..6) — Message Buffer {i} WORD_64B Register
  fields as MB0_64B_WORD10_L
{0x2B4+0x48*i} MB{i}_64B_WORD11_H (MB_SIZE view) (i=0..6) — Message Buffer {i} WORD_64B Register
  fields as MB0_64B_WORD11_L
{0x2B8+0x48*i} MB{i}_64B_WORD12_H (MB_SIZE view) (i=0..6) — Message Buffer {i} WORD_64B Register
  fields as MB0_64B_WORD12_L
{0x2BC+0x48*i} MB{i}_64B_WORD13_H (MB_SIZE view) (i=0..6) — Message Buffer {i} WORD_64B Register
  fields as MB0_64B_WORD13_L
0x2BC WORD135 (MB_SIZE view) — Message Buffer 35 WORD1 Register
  fields as MB0_16B_WORD1_L
{0x2C0+0x48*i} MB{i}_64B_WORD14_H (MB_SIZE view) (i=0..6) — Message Buffer {i} WORD_64B Register
  fields as MB0_64B_WORD14_L
{0x2C4+0x48*i} MB{i}_64B_WORD15_H (MB_SIZE view) (i=0..6) — Message Buffer {i} WORD_64B Register
  fields as MB0_64B_WORD15_L
0x2CC WORD136 (MB_SIZE view) — Message Buffer 36 WORD1 Register
  fields as MB0_16B_WORD1_L
0x2DC WORD137 (MB_SIZE view) — Message Buffer 37 WORD1 Register
  fields as MB0_16B_WORD1_L
0x2EC WORD138 (MB_SIZE view) — Message Buffer 38 WORD1 Register
  fields as MB0_16B_WORD1_L
0x2FC WORD139 (MB_SIZE view) — Message Buffer 39 WORD1 Register
  fields as MB0_16B_WORD1_L
0x30C WORD140 (MB_SIZE view) — Message Buffer 40 WORD1 Register
  fields as MB0_16B_WORD1_L
0x31C WORD141 (MB_SIZE view) — Message Buffer 41 WORD1 Register
  fields as MB0_16B_WORD1_L
0x32C WORD142 (MB_SIZE view) — Message Buffer 42 WORD1 Register
  fields as MB0_16B_WORD1_L
0x33C WORD143 (MB_SIZE view) — Message Buffer 43 WORD1 Register
  fields as MB0_16B_WORD1_L
0x34C WORD144 (MB_SIZE view) — Message Buffer 44 WORD1 Register
  fields as MB0_16B_WORD1_L
0x35C WORD145 (MB_SIZE view) — Message Buffer 45 WORD1 Register
  fields as MB0_16B_WORD1_L
0x36C WORD146 (MB_SIZE view) — Message Buffer 46 WORD1 Register
  fields as MB0_16B_WORD1_L
0x37C WORD147 (MB_SIZE view) — Message Buffer 47 WORD1 Register
  fields as MB0_16B_WORD1_L
0x38C WORD148 (MB_SIZE view) — Message Buffer 48 WORD1 Register
  fields as MB0_16B_WORD1_L
0x39C WORD149 (MB_SIZE view) — Message Buffer 49 WORD1 Register
  fields as MB0_16B_WORD1_L
0x3AC WORD150 (MB_SIZE view) — Message Buffer 50 WORD1 Register
  fields as MB0_16B_WORD1_L
0x3BC WORD151 (MB_SIZE view) — Message Buffer 51 WORD1 Register
  fields as MB0_16B_WORD1_L
0x3CC WORD152 (MB_SIZE view) — Message Buffer 52 WORD1 Register
  fields as MB0_16B_WORD1_L
0x3DC WORD153 (MB_SIZE view) — Message Buffer 53 WORD1 Register
  fields as MB0_16B_WORD1_L
0x3EC WORD154 (MB_SIZE view) — Message Buffer 54 WORD1 Register
  fields as MB0_16B_WORD1_L
0x3FC WORD155 (MB_SIZE view) — Message Buffer 55 WORD1 Register
  fields as MB0_16B_WORD1_L
0x40C WORD156 (MB_SIZE view) — Message Buffer 56 WORD1 Register
  fields as MB0_16B_WORD1_L
0x41C WORD157 (MB_SIZE view) — Message Buffer 57 WORD1 Register
  fields as MB0_16B_WORD1_L
0x42C WORD158 (MB_SIZE view) — Message Buffer 58 WORD1 Register
  fields as MB0_16B_WORD1_L
0x43C WORD159 (MB_SIZE view) — Message Buffer 59 WORD1 Register
  fields as MB0_16B_WORD1_L
0x44C WORD160 (MB_SIZE view) — Message Buffer 60 WORD1 Register
  fields as MB0_16B_WORD1_L
0x45C WORD161 (MB_SIZE view) — Message Buffer 61 WORD1 Register
  fields as MB0_16B_WORD1_L
0x46C WORD162 (MB_SIZE view) — Message Buffer 62 WORD1 Register
  fields as MB0_16B_WORD1_L
0x47C WORD163 (MB_SIZE view) — Message Buffer 63 WORD1 Register
  fields as MB0_16B_WORD1_L
{0x880+4i} RXIMR[{i}] (i=0..63) reset not defined — Rx Individual Mask Registers
  [31:0] MI — Individual Mask Bits
0xC00 FDCTRL reset 0x80000100 — CAN FD Control Register
  [31] FDRATE — Bit Rate Switch Enable
    0=nominal (Transmit a frame in nominal rate. The BRS bit in the Tx MB has no effect.); 1=bit_rate_switching (Transmit a frame with bit rate switching if the BRS bit in the Tx MB is recessive.)
  [20:19] MBDSR1 — Message Buffer Data Size for Region 1
    0=R1_8_bytes (Selects 8 bytes per message buffer.); 1=R1_16_bytes (Selects 16 bytes per message buffer.); 2=R1_32_bytes (Selects 32 bytes per message buffer.); 3=R1_64_bytes (Selects 64 bytes per message buffer.)
  [17:16] MBDSR0 — Message Buffer Data Size for Region 0
    0=R0_8_bytes (Selects 8 bytes per message buffer.); 1=R0_16_bytes (Selects 16 bytes per message buffer.); 2=R0_32_bytes (Selects 32 bytes per message buffer.); 3=R0_64_bytes (Selects 64 bytes per message buffer.)
  [15] TDCEN — Transceiver Delay Compensation Enable
    0=DISABLE (TDC is disabled); 1=ENABLE (TDC is enabled)
  [14] TDCFAIL write-1-clears — Transceiver Delay Compensation Fail
    0=in_range (Measured loop delay is in range.); 1=out_of_range (Measured loop delay is out of range.)
  [12:8] TDCOFF — Transceiver Delay Compensation Offset
  [5:0] TDCVAL ro — Transceiver Delay Compensation Value
0xC04 FDCBT — CAN FD Bit Timing Register
  [29:20] FPRESDIV — Fast Prescaler Division Factor
  [18:16] FRJW — Fast Resync Jump Width
  [14:10] FPROPSEG — Fast Propagation Segment
  [7:5] FPSEG1 — Fast Phase Segment 1
  [2:0] FPSEG2 — Fast Phase Segment 2
0xC08 FDCRC ro — CAN FD CRC Register
  [30:24] FD_MBCRC — CRC Mailbox Number for FD_TXCRC
  [20:0] FD_TXCRC — Extended Transmitted CRC value
